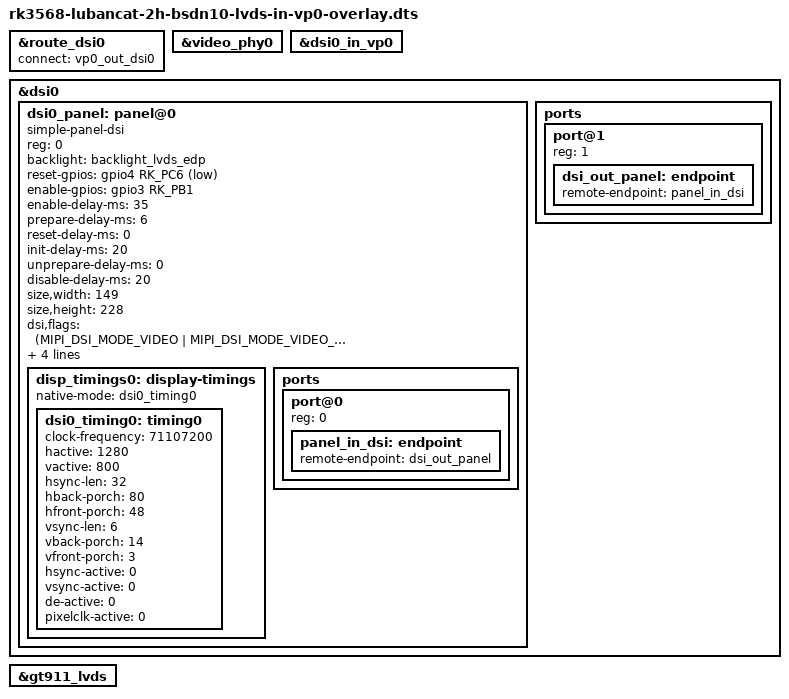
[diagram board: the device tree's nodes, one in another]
/dts-v1/;
/plugin/;

#include <dt-bindings/gpio/gpio.h>
#include <dt-bindings/pinctrl/rockchip.h>
#include <dt-bindings/display/drm_mipi_dsi.h>
#include <dt-bindings/interrupt-controller/irq.h>

/ {

	fragment@0 {
		target = <&route_dsi0>;

		__overlay__ {
			status = "okay";
			connect = <&vp0_out_dsi0>;
		};
	};

	fragment@1 {
		target = <&video_phy0>;

		__overlay__ {
			status = "okay";
		};
	};

	fragment@2 {
		target = <&dsi0_in_vp0>;

		__overlay__ {
			status = "okay";
		};
	};

	fragment@4 {
		target = <&dsi0>;

		__overlay__ {
			status = "okay";
			#address-cells = <1>;
			#size-cells = <0>;

			dsi0_panel: panel@0 {
				compatible = "simple-panel-dsi";
				reg = <0>;
				backlight = <&backlight_lvds_edp>;
				reset-gpios = <&gpio4 RK_PC6 GPIO_ACTIVE_LOW>;
				enable-gpios = <&gpio3 RK_PB1 GPIO_ACTIVE_HIGH>;
				
				enable-delay-ms = <35>;
				prepare-delay-ms = <6>;
				reset-delay-ms = <0>;
				init-delay-ms = <20>;
				unprepare-delay-ms = <0>;
				disable-delay-ms = <20>;

				size,width = <149>;
				size,height = <228>;

				dsi,flags = <(MIPI_DSI_MODE_VIDEO | MIPI_DSI_MODE_VIDEO_BURST | MIPI_DSI_MODE_LPM)>;
				dsi,format = <MIPI_DSI_FMT_RGB888>;
				dsi,lanes  = <4>;

				panel-init-sequence = [
					23 00 02 27 AA
					23 00 02 48 02
					23 00 02 B6 20
					23 00 02 01 00
					23 00 02 02 20
					23 00 02 03 35
					23 00 02 04 30
					23 00 02 05 20
					23 00 02 06 50
					23 00 02 07 00
					23 00 02 08 03
					23 00 02 09 06
					23 00 02 0A 0E
					23 00 02 0B 82
					23 00 02 0C 27
					23 00 02 0D 01
					23 00 02 0E 80
					23 00 02 0F 20
					23 00 02 10 20
					23 00 02 11 03
					23 00 02 12 1B
					23 00 02 13 03
					23 00 02 14 01
					23 00 02 15 23
					23 00 02 16 40
					23 00 02 17 00
					23 00 02 18 01
					23 00 02 19 23
					23 00 02 1A 40
					23 00 02 1B 00
					23 00 02 1E 46
					23 00 02 51 30
					23 00 02 1F 10
					23 00 02 2A 01
					//如下为SSR展频，不加可能点不亮
					23 00 02 6A	08
					23 00 02 6C	9E
					23 00 02 6D 07
					23 00 02 6E	00
					23 00 02 6F	8A
					23 00 02 70 19
					23 64 02 71 00
				];

				disp_timings0: display-timings {
					native-mode = <&dsi0_timing0>;
					dsi0_timing0: timing0 {
						clock-frequency = <71107200>;
						hactive = <1280>;
						vactive = <800>;

						hsync-len   = <32>;
						hback-porch = <80>;
						hfront-porch= <48>; 	// 1440

						vsync-len    = <6>;
						vback-porch  = <14>;
						vfront-porch = <3>;  	// 823

						hsync-active = <0>;
						vsync-active = <0>;
						de-active = <0>;
						pixelclk-active = <0>;
					};
				};

				ports {
					#address-cells = <1>;
					#size-cells = <0>;
					port@0 {
						reg = <0>;
						panel_in_dsi: endpoint {
							remote-endpoint = <&dsi_out_panel>;
						};
					};
				};
			};

			ports {
				#address-cells = <1>;
				#size-cells = <0>;

				port@1 {
					reg = <1>;
					dsi_out_panel: endpoint {
						remote-endpoint = <&panel_in_dsi>;
					};
				};
			};
		};
	};

	fragment@5 {
		target = <&gt911_lvds>;

		__overlay__ {
			status = "okay";
		};
	};
};
